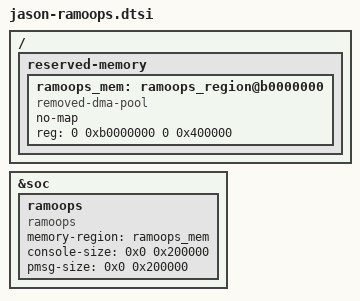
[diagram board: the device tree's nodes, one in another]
// custom
/ {
	reserved-memory {
		ramoops_mem: ramoops_region@b0000000 {
			compatible = "removed-dma-pool";
			no-map;
			reg = <0 0xb0000000 0 0x400000>;
		};
	};
};

&soc {
	ramoops {
		compatible = "ramoops";
		memory-region = <&ramoops_mem>;
		console-size = <0x0 0x200000>;
		pmsg-size = <0x0 0x200000>;
	};
};
